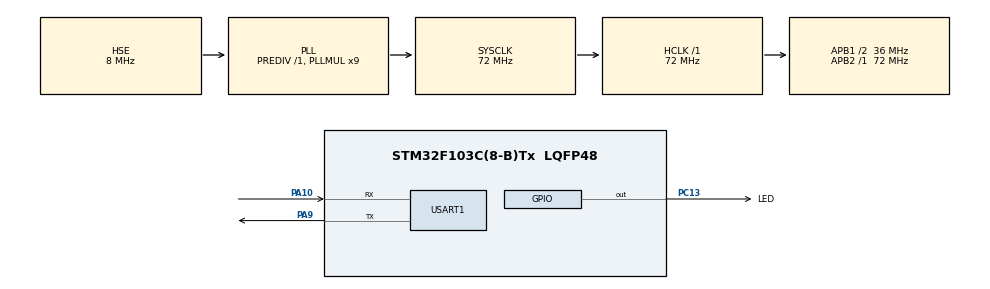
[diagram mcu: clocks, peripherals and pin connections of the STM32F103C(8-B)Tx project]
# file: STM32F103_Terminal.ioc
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Mcu.Family=STM32F1
Mcu.Name=STM32F103C(8-B)Tx
Mcu.Package=LQFP48
NVIC.PriorityGroup=NVIC_PRIORITYGROUP_4
NVIC.USART1_IRQn=true\:0\:0\:false\:false\:true\:true\:true
PA10.Mode=Asynchronous
PA10.Signal=USART1_RX
PA13.Mode=Serial_Wire
PA13.Signal=SYS_JTMS-SWDIO
PA14.Mode=Serial_Wire
PA14.Signal=SYS_JTCK-SWCLK
PA9.Mode=Asynchronous
PA9.Signal=USART1_TX
PC13-TAMPER-RTC.GPIO_Label=LED
PC13-TAMPER-RTC.GPIO_PuPd=GPIO_PULLDOWN
PC13-TAMPER-RTC.Signal=GPIO_Output
PC14-OSC32_IN.Mode=LSE-External-Oscillator
PC14-OSC32_IN.Signal=RCC_OSC32_IN
PC15-OSC32_OUT.Mode=LSE-External-Oscillator
PC15-OSC32_OUT.Signal=RCC_OSC32_OUT
PD0-OSC_IN.Mode=HSE-External-Oscillator
PD0-OSC_IN.Signal=RCC_OSC_IN
PD1-OSC_OUT.Mode=HSE-External-Oscillator
PD1-OSC_OUT.Signal=RCC_OSC_OUT
ProjectManager.HeapSize=0x200
ProjectManager.StackSize=0x400
ProjectManager.TargetToolchain=MDK-ARM V5
RCC.AHBFreq_Value=72000000
RCC.APB1CLKDivider=RCC_HCLK_DIV2
RCC.APB1Freq_Value=36000000
RCC.APB1TimFreq_Value=72000000
RCC.APB2Freq_Value=72000000
RCC.APB2TimFreq_Value=72000000
RCC.HCLKFreq_Value=72000000
RCC.PLLMUL=RCC_PLL_MUL9
RCC.PLLSourceVirtual=RCC_PLLSOURCE_HSE
RCC.SYSCLKFreq_VALUE=72000000
RCC.SYSCLKSource=RCC_SYSCLKSOURCE_PLLCLK
RCC.USBFreq_Value=72000000
USART1.VirtualMode=VM_ASYNC
board=custom

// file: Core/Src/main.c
/* USER CODE BEGIN Header */
/**
  ******************************************************************************
  * @file           : main.c
  * @brief          : Main program body
  ******************************************************************************
  * @attention
  *
  * <h2><center>&copy; Copyright (c) 2022 STMicroelectronics.
  * All rights reserved.</center></h2>
  *
  * This software component is licensed by ST under BSD 3-Clause license,
  * the "License"; You may not use this file except in compliance with the
  * License. You may obtain a copy of the License at:
  *                        opensource.org/licenses/BSD-3-Clause
  *
  ******************************************************************************
  */
/* USER CODE END Header */
#include "main.h"

/* USER CODE BEGIN Includes */
#include "terminal.h"
/* USER CODE END Includes */

void SystemClock_Config(void);
static void MX_GPIO_Init(void);
static void MX_USART1_UART_Init(void);

/* USER CODE BEGIN 0 */
#pragma import(__use_no_semihosting)
struct __FILE
{
    int handle;
};

FILE __stdout;
void _sys_exit(int x)
{
    x = x;
}

int fputc(int ch, FILE *f)
{
    while ((USART1->SR & 0X40) == 0)
        ;
    USART1->DR = (uint8_t)ch;
    return ch;
}

void LED_ctr(void)
{
  HAL_GPIO_WritePin(LED_GPIO_Port,LED_Pin, CLI_GetArgDec(0)?0:1);
}
/* USER CODE END 0 */

int main(void)
{

  /* MCU Configuration--------------------------------------------------------*/

  /* Reset of all peripherals, Initializes the Flash interface and the Systick. */
  HAL_Init();

  /* Configure the system clock */
  SystemClock_Config();

  /* Initialize all configured peripherals */
  MX_GPIO_Init();
  MX_USART1_UART_Init();
  /* USER CODE BEGIN 2 */
  LL_USART_EnableIT_RXNE(USART1);
   CLI_Init(TDC_All);
   CLI_AddCmd("LED", 	LED_ctr, 	1, TMC_None, "set led output");
  /* USER CODE END 2 */

  /* Infinite loop */
  while (1)
  {

    /* USER CODE BEGIN 3 */
    CLI_Execute();
  }
  /* USER CODE END 3 */
}

void SystemClock_Config(void)
{
  RCC_OscInitTypeDef RCC_OscInitStruct = {0};
  RCC_ClkInitTypeDef RCC_ClkInitStruct = {0};

  /** Initializes the RCC Oscillators according to the specified parameters
  * in the RCC_OscInitTypeDef structure.
  */
  RCC_OscInitStruct.OscillatorType = RCC_OSCILLATORTYPE_HSE;
  RCC_OscInitStruct.HSEState = RCC_HSE_ON;
  RCC_OscInitStruct.HSEPredivValue = RCC_HSE_PREDIV_DIV1;
  RCC_OscInitStruct.HSIState = RCC_HSI_ON;
  RCC_OscInitStruct.PLL.PLLState = RCC_PLL_ON;
  RCC_OscInitStruct.PLL.PLLSource = RCC_PLLSOURCE_HSE;
  RCC_OscInitStruct.PLL.PLLMUL = RCC_PLL_MUL9;
  if (HAL_RCC_OscConfig(&RCC_OscInitStruct) != HAL_OK)
  {
    Error_Handler();
  }
  /** Initializes the CPU, AHB and APB buses clocks
  */
  RCC_ClkInitStruct.ClockType = RCC_CLOCKTYPE_HCLK|RCC_CLOCKTYPE_SYSCLK
                              |RCC_CLOCKTYPE_PCLK1|RCC_CLOCKTYPE_PCLK2;
  RCC_ClkInitStruct.SYSCLKSource = RCC_SYSCLKSOURCE_PLLCLK;
  RCC_ClkInitStruct.AHBCLKDivider = RCC_SYSCLK_DIV1;
  RCC_ClkInitStruct.APB1CLKDivider = RCC_HCLK_DIV2;
  RCC_ClkInitStruct.APB2CLKDivider = RCC_HCLK_DIV1;

  if (HAL_RCC_ClockConfig(&RCC_ClkInitStruct, FLASH_LATENCY_2) != HAL_OK)
  {
    Error_Handler();
  }
}

static void MX_USART1_UART_Init(void)
{

  LL_USART_InitTypeDef USART_InitStruct = {0};

  LL_GPIO_InitTypeDef GPIO_InitStruct = {0};

  /* Peripheral clock enable */
  LL_APB2_GRP1_EnableClock(LL_APB2_GRP1_PERIPH_USART1);

  LL_APB2_GRP1_EnableClock(LL_APB2_GRP1_PERIPH_GPIOA);
  /**USART1 GPIO Configuration
  PA9   ------> USART1_TX
  PA10   ------> USART1_RX
  */
  GPIO_InitStruct.Pin = LL_GPIO_PIN_9;
  GPIO_InitStruct.Mode = LL_GPIO_MODE_ALTERNATE;
  GPIO_InitStruct.Speed = LL_GPIO_SPEED_FREQ_HIGH;
  GPIO_InitStruct.OutputType = LL_GPIO_OUTPUT_PUSHPULL;
  LL_GPIO_Init(GPIOA, &GPIO_InitStruct);

  GPIO_InitStruct.Pin = LL_GPIO_PIN_10;
  GPIO_InitStruct.Mode = LL_GPIO_MODE_FLOATING;
  LL_GPIO_Init(GPIOA, &GPIO_InitStruct);

  /* USART1 interrupt Init */
  NVIC_SetPriority(USART1_IRQn, NVIC_EncodePriority(NVIC_GetPriorityGrouping(),0, 0));
  NVIC_EnableIRQ(USART1_IRQn);

  USART_InitStruct.BaudRate = 115200;
  USART_InitStruct.DataWidth = LL_USART_DATAWIDTH_8B;
  USART_InitStruct.StopBits = LL_USART_STOPBITS_1;
  USART_InitStruct.Parity = LL_USART_PARITY_NONE;
  USART_InitStruct.TransferDirection = LL_USART_DIRECTION_TX_RX;
  USART_InitStruct.HardwareFlowControl = LL_USART_HWCONTROL_NONE;
  USART_InitStruct.OverSampling = LL_USART_OVERSAMPLING_16;
  LL_USART_Init(USART1, &USART_InitStruct);
  LL_USART_ConfigAsyncMode(USART1);
  LL_USART_Enable(USART1);

}

static void MX_GPIO_Init(void)
{
  GPIO_InitTypeDef GPIO_InitStruct = {0};

  /* GPIO Ports Clock Enable */
  __HAL_RCC_GPIOC_CLK_ENABLE();
  __HAL_RCC_GPIOD_CLK_ENABLE();
  __HAL_RCC_GPIOA_CLK_ENABLE();

  /*Configure GPIO pin Output Level */
  HAL_GPIO_WritePin(LED_GPIO_Port, LED_Pin, GPIO_PIN_RESET);

  /*Configure GPIO pin : LED_Pin */
  GPIO_InitStruct.Pin = LED_Pin;
  GPIO_InitStruct.Mode = GPIO_MODE_OUTPUT_PP;
  GPIO_InitStruct.Pull = GPIO_PULLDOWN;
  GPIO_InitStruct.Speed = GPIO_SPEED_FREQ_LOW;
  HAL_GPIO_Init(LED_GPIO_Port, &GPIO_InitStruct);

}

void Error_Handler(void)
{
  __disable_irq();
  while (1)
  {
  }
}

/************************ (C) COPYRIGHT STMicroelectronics *****END OF FILE****/
